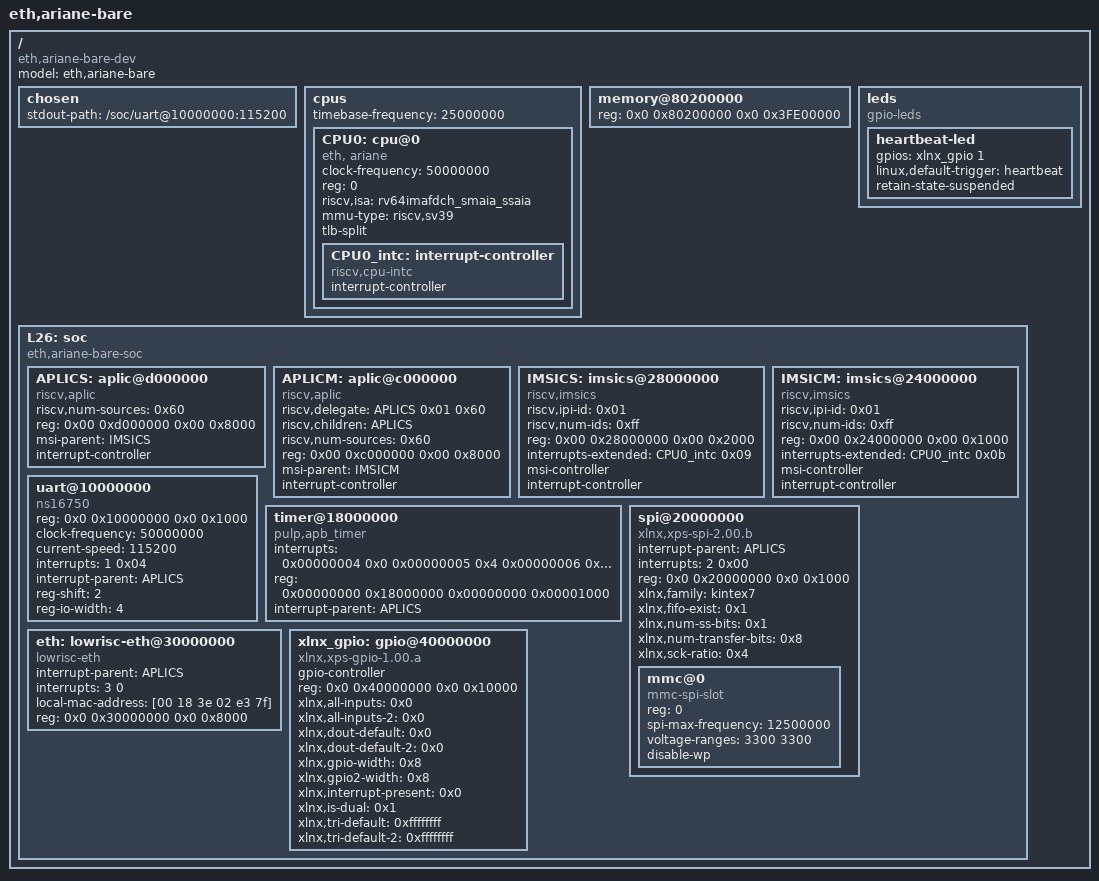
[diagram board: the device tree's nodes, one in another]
/dts-v1/;

/ {
  #address-cells = <2>;
  #size-cells = <2>;
  compatible = "eth,ariane-bare-dev";
  model = "eth,ariane-bare";
  chosen {
    stdout-path = "/soc/uart@10000000:115200";
  };
  cpus {
    #address-cells = <1>;
    #size-cells = <0>;
    timebase-frequency = <25000000>; // 25 MHz
    CPU0: cpu@0 {
      clock-frequency = <50000000>; // 50 MHz
      device_type = "cpu";
      reg = <0>;
      status = "okay";
      compatible = "eth, ariane", "riscv";
      riscv,isa = "rv64imafdch_smaia_ssaia";
      mmu-type = "riscv,sv39";
      tlb-split;
      CPU0_intc: interrupt-controller {
				#interrupt-cells = <0x01>;
				interrupt-controller;
				compatible = "riscv,cpu-intc";
				phandle = <0x02>;
			};
    };
  };
  memory@80200000 {
    device_type = "memory";
    reg = <0x0 0x80200000 0x0 0x3FE00000>;
  };
  leds {
    compatible = "gpio-leds";
    heartbeat-led {
      gpios = <&xlnx_gpio 1 0>;
      linux,default-trigger = "heartbeat";
      retain-state-suspended;
    };
  };
  L26: soc {
    #address-cells = <2>;
    #size-cells = <2>;
    compatible = "eth,ariane-bare-soc", "simple-bus";
    ranges;

    APLICS: aplic@d000000 {
			phandle = <0x06>;
			riscv,num-sources = <0x60>;
			reg = <0x00 0xd000000 0x00 0x8000>;
			msi-parent = <&IMSICS>;
			interrupt-controller;
			#interrupt-cells = <0x02>;
			compatible = "riscv,aplic";
		};

		APLICM: aplic@c000000 {
			phandle = <0x05>;
			riscv,delegate = <&APLICS 0x01 0x60>;
			riscv,children = <&APLICS>;
			riscv,num-sources = <0x60>;
			reg = <0x00 0xc000000 0x00 0x8000>;
			msi-parent = <&IMSICM>;
			interrupt-controller;
			#interrupt-cells = <0x02>;
			compatible = "riscv,aplic";
		};

		IMSICS: imsics@28000000 {
			phandle = <0x04>;
			riscv,ipi-id = <0x01>;
			riscv,num-ids = <0xff>;
			reg = <0x00 0x28000000 0x00 0x2000>;
			interrupts-extended = <&CPU0_intc 0x09>;
			msi-controller;
			interrupt-controller;
			#interrupt-cells = <0x00>;
			compatible = "riscv,imsics";
		};

		IMSICM: imsics@24000000 {
			phandle = <0x03>;
			riscv,ipi-id = <0x01>;
			riscv,num-ids = <0xff>;
			reg = <0x00 0x24000000 0x00 0x1000>;
			interrupts-extended = <&CPU0_intc 0x0b>;
			msi-controller;
			interrupt-controller;
			#interrupt-cells = <0x00>;
			compatible = "riscv,imsics";
		};

    uart@10000000 {
      compatible = "ns16750";
      reg = <0x0 0x10000000 0x0 0x1000>;
      clock-frequency = <50000000>;
      current-speed = <115200>;
      interrupts = <1 0x04>;
      interrupt-parent = <&APLICS>;
      reg-shift = <2>; // regs are spaced on 32 bit boundary
      reg-io-width = <4>; // only 32-bit access are supported
    };

    timer@18000000 {
      compatible = "pulp,apb_timer";
      interrupts = <0x00000004 0x0 
                    0x00000005 0x4
                    0x00000006 0x0
                    0x00000007 0x0>;
      reg = <0x00000000 0x18000000 0x00000000 0x00001000>;
      interrupt-parent = <&APLICS>;
      reg-names = "control";
    };

    spi@20000000 {
      compatible = "xlnx,xps-spi-2.00.b", "xlnx,xps-spi-2.00.a";
      #address-cells = <1>;
      #size-cells = <0>;
      interrupt-parent = <&APLICS>;
      interrupts = <2 0x00>;
      reg = < 0x0 0x20000000 0x0 0x1000 >;
      xlnx,family = "kintex7";
      xlnx,fifo-exist = <0x1>;
      xlnx,num-ss-bits = <0x1>;
      xlnx,num-transfer-bits = <0x8>;
      xlnx,sck-ratio = <0x4>;

      mmc@0 {
        compatible = "mmc-spi-slot";
        reg = <0>;
        spi-max-frequency = <12500000>;
        voltage-ranges = <3300 3300>;
        disable-wp;
      };
    };

    eth: lowrisc-eth@30000000 {
      compatible = "lowrisc-eth";
      device_type = "network";
      interrupt-parent = <&APLICS>;
      interrupts = <3 0>;
      local-mac-address = [00 18 3e 02 e3 7f]; // This needs to change if more than one GenesysII on a VLAN
      reg = <0x0 0x30000000 0x0 0x8000>;
    };

    xlnx_gpio: gpio@40000000 {
      #gpio-cells = <2>;
      compatible = "xlnx,xps-gpio-1.00.a";
      gpio-controller ;
      reg = <0x0 0x40000000 0x0 0x10000 >;
      xlnx,all-inputs = <0x0>;
      xlnx,all-inputs-2 = <0x0>;
      xlnx,dout-default = <0x0>;
      xlnx,dout-default-2 = <0x0>;
      xlnx,gpio-width = <0x8>;
      xlnx,gpio2-width = <0x8>;
      xlnx,interrupt-present = <0x0>;
      xlnx,is-dual = <0x1>;
      xlnx,tri-default = <0xffffffff>;
      xlnx,tri-default-2 = <0xffffffff>;
    };
  };
};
